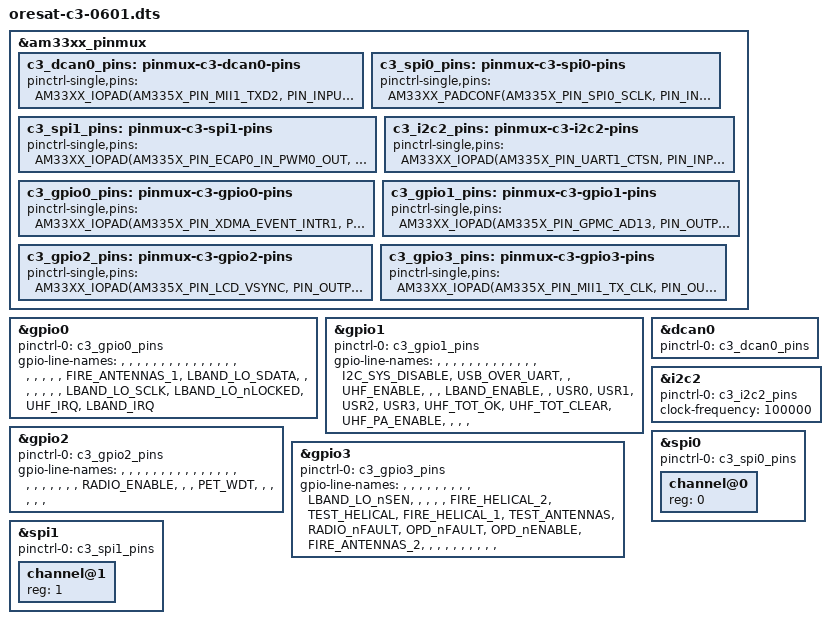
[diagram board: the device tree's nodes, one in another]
/* OreSat C3 v6.1 device tree */

/dts-v1/;

#include "oresat-base.dtsi"

&am33xx_pinmux {
  c3_dcan0_pins: pinmux-c3-dcan0-pins {
    pinctrl-single,pins = <
      AM33XX_IOPAD(AM335X_PIN_MII1_TXD2, PIN_INPUT_PULLUP | MUX_MODE1) /* dcan0_rx */
      AM33XX_IOPAD(AM335X_PIN_MII1_TXD3, PIN_OUTPUT_PULLUP | MUX_MODE1) /* dcan0_tx */
    >;
  };

  c3_spi0_pins: pinmux-c3-spi0-pins {
    pinctrl-single,pins = <
      AM33XX_PADCONF(AM335X_PIN_SPI0_SCLK, PIN_INPUT_PULLUP, MUX_MODE0) /* spi0_sclk */
      AM33XX_PADCONF(AM335X_PIN_SPI0_D0, PIN_INPUT_PULLUP, MUX_MODE0) /* spi0_d0 */
      AM33XX_PADCONF(AM335X_PIN_SPI0_D1, PIN_OUTPUT_PULLUP, MUX_MODE0) /* spi0_d1 */
      AM33XX_PADCONF(AM335X_PIN_SPI0_CS0, PIN_OUTPUT_PULLUP, MUX_MODE0) /* spi0_cs0 */
    >;
  };

  c3_spi1_pins: pinmux-c3-spi1-pins {
    pinctrl-single,pins = <
      AM33XX_IOPAD(AM335X_PIN_ECAP0_IN_PWM0_OUT, PIN_INPUT_PULLUP | MUX_MODE4) /* spi1_sclk */
      AM33XX_IOPAD(AM335X_PIN_UART0_CTSN, PIN_INPUT_PULLUP | MUX_MODE4) /* spi1_d0 */
      AM33XX_IOPAD(AM335X_PIN_UART0_RTSN, PIN_OUTPUT_PULLUP | MUX_MODE4) /* spi1_d1 */
      AM33XX_IOPAD(AM335X_PIN_XDMA_EVENT_INTR0, PIN_OUTPUT_PULLUP | MUX_MODE4) /* spi1_cs1 */
    >;
  };

  c3_i2c2_pins: pinmux-c3-i2c2-pins {
    pinctrl-single,pins = <
      AM33XX_IOPAD(AM335X_PIN_UART1_CTSN, PIN_INPUT | MUX_MODE3) /* i2c2_sda */
      AM33XX_IOPAD(AM335X_PIN_UART1_RTSN, PIN_INPUT | MUX_MODE3) /* i2c2_scl */
    >;
  };

  c3_gpio0_pins: pinmux-c3-gpio0-pins {
    pinctrl-single,pins = <
      AM33XX_IOPAD(AM335X_PIN_XDMA_EVENT_INTR1, PIN_INPUT | MUX_MODE7) /* gpio0_20 / FIRE_ANTENNAS_1 */
      AM33XX_IOPAD(AM335X_PIN_MII1_TXD1, PIN_OUTPUT | MUX_MODE7) /* gpio0_21 / LBAND_LO_SDATA */
      AM33XX_IOPAD(AM335X_PIN_MII1_TXD0, PIN_OUTPUT | MUX_MODE7) /* gpio0_28 / LBAND_LO_SCLK */
      AM33XX_IOPAD(AM335X_PIN_RMII1_REF_CLK, PIN_INPUT | MUX_MODE7) /* gpio0_29 / LBAND_LO_nLOCKED */
      AM33XX_IOPAD(AM335X_PIN_GPMC_WAIT0, PIN_INPUT | PIN_INPUT_PULLDOWN | MUX_MODE7) /* gpio0_30 / UHF_IRQ */
      AM33XX_IOPAD(AM335X_PIN_GPMC_WPN, PIN_INPUT | PIN_INPUT_PULLDOWN | MUX_MODE7) /* gpio0_31 / LBAND_IRQ */
    >;
  };

  c3_gpio1_pins: pinmux-c3-gpio1-pins {
    pinctrl-single,pins = <
      AM33XX_IOPAD(AM335X_PIN_GPMC_AD13, PIN_OUTPUT | MUX_MODE7) /* gpio1_13 / I2C_SYS_DISABLE */
      AM33XX_IOPAD(AM335X_PIN_GPMC_AD14, PIN_OUTPUT | MUX_MODE7) /* gpio1_14 / USB_OVER_UART */
      AM33XX_IOPAD(AM335X_PIN_GPMC_A0, PIN_OUTPUT | MUX_MODE7) /* gpio1_16 / UHF_ENABLE */
      AM33XX_IOPAD(AM335X_PIN_GPMC_A3, PIN_OUTPUT | MUX_MODE7) /* gpio1_19 / LBAND_ENABLE */
      AM33XX_IOPAD(AM335X_PIN_GPMC_A9, PIN_INPUT | MUX_MODE7) /* gpio1_25 / UHF_TOT_OK */
      AM33XX_IOPAD(AM335X_PIN_GPMC_A10, PIN_OUTPUT | MUX_MODE7) /* gpio1_26 / UHF_TOT_CLEAR */
      AM33XX_IOPAD(AM335X_PIN_GPMC_A11, PIN_OUTPUT | MUX_MODE7) /* gpio1_27 / UHF_PA_ENABLE */
    >;
  };

  c3_gpio2_pins: pinmux-c3-gpio2-pins {
    pinctrl-single,pins = <
      AM33XX_IOPAD(AM335X_PIN_LCD_VSYNC, PIN_OUTPUT | MUX_MODE7) /* gpio2_22 / RADIO_ENABLE */
      AM33XX_IOPAD(AM335X_PIN_LCD_AC_BIAS_EN, PIN_OUTPUT | MUX_MODE7) /* gpio2_25 / PET_WDT */
    >;
  };

  c3_gpio3_pins: pinmux-c3-gpio3-pins {
    pinctrl-single,pins = <
      AM33XX_IOPAD(AM335X_PIN_MII1_TX_CLK, PIN_OUTPUT | MUX_MODE7) /* gpio3_9 / LBAND_LO_nSEN */
      AM33XX_IOPAD(AM335X_PIN_MCASP0_ACLKX, PIN_INPUT | MUX_MODE7) /* gpio3_14 / FIRE_HELICAL_2 */
      AM33XX_IOPAD(AM335X_PIN_MCASP0_FSX, PIN_OUTPUT | MUX_MODE7) /* gpio3_15 / TEST_HELICAL */
      AM33XX_IOPAD(AM335X_PIN_MCASP0_AXR0, PIN_INPUT | MUX_MODE7) /* gpio3_16 / FIRE_HELICAL_1 */
      AM33XX_IOPAD(AM335X_PIN_MCASP0_AHCLKR, PIN_OUTPUT | MUX_MODE7) /* gpio3_17 / TEST_ANTENNAS */
      AM33XX_IOPAD(AM335X_PIN_MCASP0_ACLKR, PIN_INPUT | MUX_MODE7) /* gpio3_18 / RADIO_nFAULT */
      AM33XX_IOPAD(AM335X_PIN_MCASP0_FSR, PIN_INPUT | MUX_MODE7) /* gpio3_19 / OPD_nFAULT */
      AM33XX_IOPAD(AM335X_PIN_MCASP0_AXR1, PIN_OUTPUT | MUX_MODE7) /* gpio3_20 / OPD_nENABLE */
      AM33XX_IOPAD(AM335X_PIN_MCASP0_AHCLKX, PIN_INPUT | MUX_MODE7) /* gpio3_21 / FIRE_ANTENNAS_2 */
    >;
  };
};

&gpio0 {
  pinctrl-names = "default";
  pinctrl-0 = <&c3_gpio0_pins>;
  gpio-line-names =
    /* 0 */ "",
    /* 1 */ "",
    /* 2 */ "",
    /* 3 */ "",
    /* 4 */ "",
    /* 5 */ "",
    /* 6 */ "",
    /* 7 */ "",
    /* 8 */ "",
    /* 9 */ "",
    /* 10 */ "",
    /* 11 */ "",
    /* 12 */ "",
    /* 13 */ "",
    /* 14 */ "",
    /* 15 */ "",
    /* 16 */ "",
    /* 17 */ "",
    /* 18 */ "",
    /* 19 */ "",
    /* 20 */ "FIRE_ANTENNAS_1",
    /* 21 */ "LBAND_LO_SDATA",
    /* 22 */ "",
    /* 23 */ "",
    /* 24 */ "",
    /* 25 */ "",
    /* 26 */ "",
    /* 27 */ "",
    /* 28 */ "LBAND_LO_SCLK",
    /* 29 */ "LBAND_LO_nLOCKED",
    /* 30 */ "UHF_IRQ",
    /* 31 */ "LBAND_IRQ";
};

&gpio1 {
  pinctrl-names = "default";
  pinctrl-0 = <&c3_gpio1_pins>;
  gpio-line-names =
    /* 0 */ "",
    /* 1 */ "",
    /* 2 */ "",
    /* 3 */ "",
    /* 4 */ "",
    /* 5 */ "",
    /* 6 */ "",
    /* 7 */ "",
    /* 8 */ "",
    /* 9 */ "",
    /* 10 */ "",
    /* 11 */ "",
    /* 12 */ "",
    /* 13 */ "I2C_SYS_DISABLE",
    /* 14 */ "USB_OVER_UART",
    /* 15 */ "",
    /* 16 */ "UHF_ENABLE",
    /* 17 */ "",
    /* 18 */ "",
    /* 19 */ "LBAND_ENABLE",
    /* 20 */ "",
    /* 21 */ "USR0",
    /* 22 */ "USR1",
    /* 23 */ "USR2",
    /* 24 */ "USR3",
    /* 25 */ "UHF_TOT_OK",
    /* 26 */ "UHF_TOT_CLEAR",
    /* 27 */ "UHF_PA_ENABLE",
    /* 28 */ "",
    /* 29 */ "",
    /* 30 */ "",
    /* 31 */ "";
};

&gpio2 {
  pinctrl-names = "default";
  pinctrl-0 = <&c3_gpio2_pins>;
  gpio-line-names =
    /* 0 */ "",
    /* 1 */ "",
    /* 2 */ "",
    /* 3 */ "",
    /* 4 */ "",
    /* 5 */ "",
    /* 6 */ "",
    /* 7 */ "",
    /* 8 */ "",
    /* 9 */ "",
    /* 10 */ "",
    /* 11 */ "",
    /* 12 */ "",
    /* 13 */ "",
    /* 14 */ "",
    /* 15 */ "",
    /* 16 */ "",
    /* 17 */ "",
    /* 18 */ "",
    /* 19 */ "",
    /* 20 */ "",
    /* 21 */ "",
    /* 22 */ "RADIO_ENABLE",
    /* 23 */ "",
    /* 24 */ "",
    /* 25 */ "PET_WDT",
    /* 26 */ "",
    /* 27 */ "",
    /* 28 */ "",
    /* 29 */ "",
    /* 30 */ "",
    /* 31 */ "";
};

&gpio3 {
  pinctrl-names = "default";
  pinctrl-0 = <&c3_gpio3_pins>;
  gpio-line-names =
    /* 0 */ "",
    /* 1 */ "",
    /* 2 */ "",
    /* 3 */ "",
    /* 4 */ "",
    /* 5 */ "",
    /* 6 */ "",
    /* 7 */ "",
    /* 8 */ "",
    /* 9 */ "LBAND_LO_nSEN",
    /* 10 */ "",
    /* 11 */ "",
    /* 12 */ "",
    /* 13 */ "",
    /* 14 */ "FIRE_HELICAL_2",
    /* 15 */ "TEST_HELICAL",
    /* 16 */ "FIRE_HELICAL_1",
    /* 17 */ "TEST_ANTENNAS",
    /* 18 */ "RADIO_nFAULT",
    /* 19 */ "OPD_nFAULT",
    /* 20 */ "OPD_nENABLE",
    /* 21 */ "FIRE_ANTENNAS_2",
    /* 22 */ "",
    /* 23 */ "",
    /* 24 */ "",
    /* 25 */ "",
    /* 26 */ "",
    /* 27 */ "",
    /* 28 */ "",
    /* 29 */ "",
    /* 30 */ "",
    /* 31 */ "";
};

&dcan0 {
  status = "okay";
  pinctrl-names = "default";
  pinctrl-0 = <&c3_dcan0_pins>;
};

&i2c2 {
  #address-cells = <1>;
  #size-cells = <0>;
  status = "okay";
  pinctrl-names = "default";
  pinctrl-0 = <&c3_i2c2_pins>;
  clock-frequency = <100000>;
};

&spi0 {
  #address-cells = <1>;
  #size-cells = <0>;
  status = "okay";
  pinctrl-names = "default";
  pinctrl-0 = <&c3_spi0_pins>;

  channel@0 {
    status = "okay";
    reg = <0>;
  };
};

&spi1 {
  #address-cells = <1>;
  #size-cells = <0>;
  status = "okay";
  pinctrl-names = "default";
  pinctrl-0 = <&c3_spi1_pins>;

  channel@1 {
    status = "okay";
    reg = <1>;
  };
};
